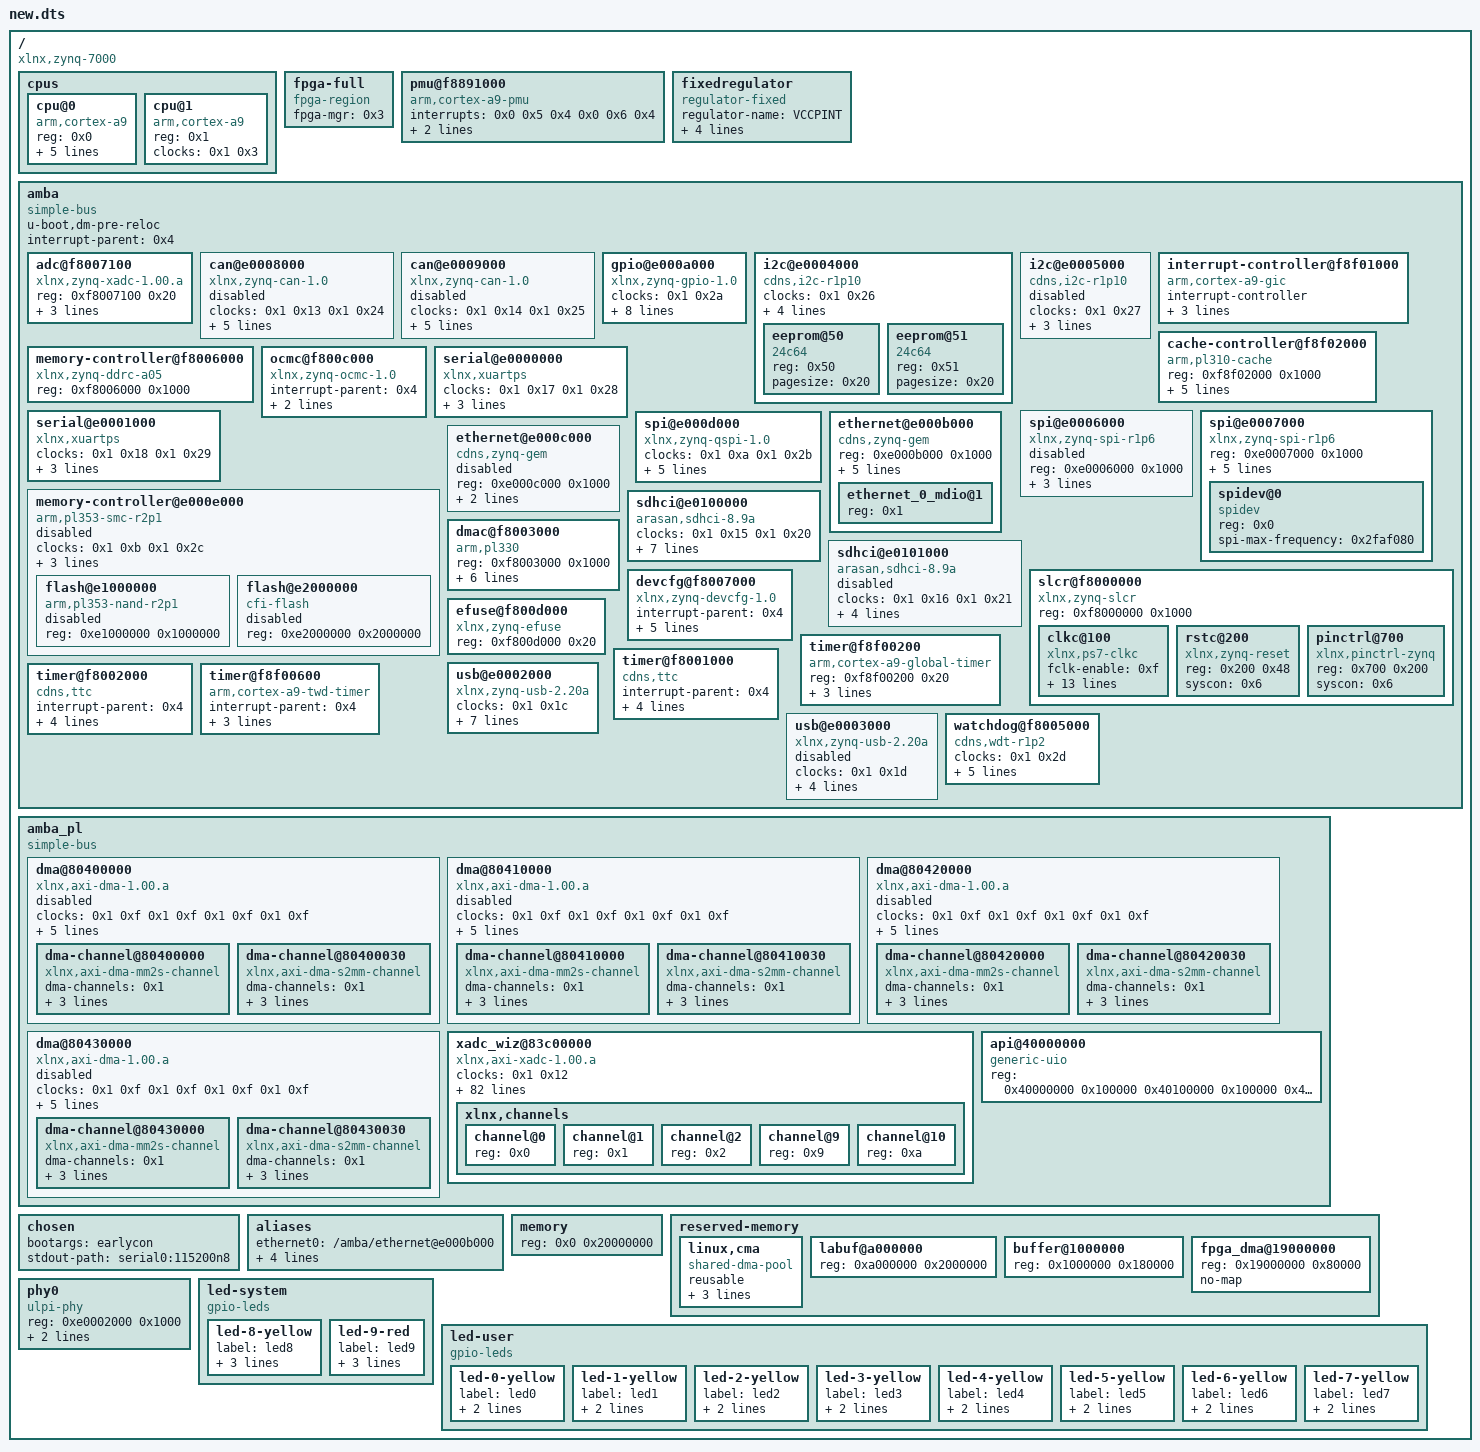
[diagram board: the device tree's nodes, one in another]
/dts-v1/;

/ {
	#address-cells = <0x1>;
	#size-cells = <0x1>;
	compatible = "xlnx,zynq-7000";

	cpus {
		#address-cells = <0x1>;
		#size-cells = <0x0>;

		cpu@0 {
			compatible = "arm,cortex-a9";
			device_type = "cpu";
			reg = <0x0>;
			clocks = <0x1 0x3>;
			clock-latency = <0x3e8>;
			cpu0-supply = <0x2>;
			operating-points = <0xa2c2a 0xf4240 0x51615 0xf4240>;
			linux,phandle = <0x9>;
			phandle = <0x9>;
		};

		cpu@1 {
			compatible = "arm,cortex-a9";
			device_type = "cpu";
			reg = <0x1>;
			clocks = <0x1 0x3>;
			linux,phandle = <0xa>;
			phandle = <0xa>;
		};
	};

	fpga-full {
		compatible = "fpga-region";
		fpga-mgr = <0x3>;
		#address-cells = <0x1>;
		#size-cells = <0x1>;
		ranges;
		linux,phandle = <0xb>;
		phandle = <0xb>;
	};

	pmu@f8891000 {
		compatible = "arm,cortex-a9-pmu";
		interrupts = <0x0 0x5 0x4 0x0 0x6 0x4>;
		interrupt-parent = <0x4>;
		reg = <0xf8891000 0x1000 0xf8893000 0x1000>;
	};

	fixedregulator {
		compatible = "regulator-fixed";
		regulator-name = "VCCPINT";
		regulator-min-microvolt = <0xf4240>;
		regulator-max-microvolt = <0xf4240>;
		regulator-boot-on;
		regulator-always-on;
		linux,phandle = <0x2>;
		phandle = <0x2>;
	};

	amba {
		u-boot,dm-pre-reloc;
		compatible = "simple-bus";
		#address-cells = <0x1>;
		#size-cells = <0x1>;
		interrupt-parent = <0x4>;
		ranges;
		linux,phandle = <0xc>;
		phandle = <0xc>;

		adc@f8007100 {
			compatible = "xlnx,zynq-xadc-1.00.a";
			reg = <0xf8007100 0x20>;
			interrupts = <0x0 0x7 0x4>;
			interrupt-parent = <0x4>;
			clocks = <0x1 0xc>;
			linux,phandle = <0xd>;
			phandle = <0xd>;
		};

		can@e0008000 {
			compatible = "xlnx,zynq-can-1.0";
			status = "disabled";
			clocks = <0x1 0x13 0x1 0x24>;
			clock-names = "can_clk", "pclk";
			reg = <0xe0008000 0x1000>;
			interrupts = <0x0 0x1c 0x4>;
			interrupt-parent = <0x4>;
			tx-fifo-depth = <0x40>;
			rx-fifo-depth = <0x40>;
			linux,phandle = <0xe>;
			phandle = <0xe>;
		};

		can@e0009000 {
			compatible = "xlnx,zynq-can-1.0";
			status = "disabled";
			clocks = <0x1 0x14 0x1 0x25>;
			clock-names = "can_clk", "pclk";
			reg = <0xe0009000 0x1000>;
			interrupts = <0x0 0x33 0x4>;
			interrupt-parent = <0x4>;
			tx-fifo-depth = <0x40>;
			rx-fifo-depth = <0x40>;
			linux,phandle = <0xf>;
			phandle = <0xf>;
		};

		gpio@e000a000 {
			compatible = "xlnx,zynq-gpio-1.0";
			#gpio-cells = <0x2>;
			clocks = <0x1 0x2a>;
			gpio-controller;
			interrupt-controller;
			#interrupt-cells = <0x2>;
			interrupt-parent = <0x4>;
			interrupts = <0x0 0x14 0x4>;
			reg = <0xe000a000 0x1000>;
			emio-gpio-width = <0x18>;
			gpio-mask-high = <0x0>;
			gpio-mask-low = <0x5600>;
			linux,phandle = <0x7>;
			phandle = <0x7>;
		};

		i2c@e0004000 {
			compatible = "cdns,i2c-r1p10";
			status = "okay";
			clocks = <0x1 0x26>;
			interrupt-parent = <0x4>;
			interrupts = <0x0 0x19 0x4>;
			reg = <0xe0004000 0x1000>;
			#address-cells = <0x1>;
			#size-cells = <0x0>;
			clock-frequency = <0x61a80>;
			linux,phandle = <0x10>;
			phandle = <0x10>;

			eeprom@50 {
				compatible = "24c64";
				reg = <0x50>;
				pagesize = <0x20>;
			};

			eeprom@51 {
				compatible = "24c64";
				reg = <0x51>;
				pagesize = <0x20>;
			};
		};

		i2c@e0005000 {
			compatible = "cdns,i2c-r1p10";
			status = "disabled";
			clocks = <0x1 0x27>;
			interrupt-parent = <0x4>;
			interrupts = <0x0 0x30 0x4>;
			reg = <0xe0005000 0x1000>;
			#address-cells = <0x1>;
			#size-cells = <0x0>;
			linux,phandle = <0x11>;
			phandle = <0x11>;
		};

		interrupt-controller@f8f01000 {
			compatible = "arm,cortex-a9-gic";
			#interrupt-cells = <0x3>;
			interrupt-controller;
			reg = <0xf8f01000 0x1000 0xf8f00100 0x100>;
			num_cpus = <0x2>;
			num_interrupts = <0x60>;
			linux,phandle = <0x4>;
			phandle = <0x4>;
		};

		cache-controller@f8f02000 {
			compatible = "arm,pl310-cache";
			reg = <0xf8f02000 0x1000>;
			interrupts = <0x0 0x2 0x4>;
			arm,data-latency = <0x3 0x2 0x2>;
			arm,tag-latency = <0x2 0x2 0x2>;
			cache-unified;
			cache-level = <0x2>;
			linux,phandle = <0x12>;
			phandle = <0x12>;
		};

		memory-controller@f8006000 {
			compatible = "xlnx,zynq-ddrc-a05";
			reg = <0xf8006000 0x1000>;
			linux,phandle = <0x13>;
			phandle = <0x13>;
		};

		ocmc@f800c000 {
			compatible = "xlnx,zynq-ocmc-1.0";
			interrupt-parent = <0x4>;
			interrupts = <0x0 0x3 0x4>;
			reg = <0xf800c000 0x1000>;
			linux,phandle = <0x14>;
			phandle = <0x14>;
		};

		serial@e0000000 {
			compatible = "xlnx,xuartps", "cdns,uart-r1p8";
			status = "okay";
			clocks = <0x1 0x17 0x1 0x28>;
			clock-names = "uart_clk", "pclk";
			reg = <0xe0000000 0x1000>;
			interrupts = <0x0 0x1b 0x4>;
			device_type = "serial";
			port-number = <0x0>;
			linux,phandle = <0x15>;
			phandle = <0x15>;
		};

		serial@e0001000 {
			compatible = "xlnx,xuartps", "cdns,uart-r1p8";
			status = "okay";
			clocks = <0x1 0x18 0x1 0x29>;
			clock-names = "uart_clk", "pclk";
			reg = <0xe0001000 0x1000>;
			interrupts = <0x0 0x32 0x4>;
			device_type = "serial";
			port-number = <0x1>;
			linux,phandle = <0x16>;
			phandle = <0x16>;
		};

		spi@e0006000 {
			compatible = "xlnx,zynq-spi-r1p6";
			reg = <0xe0006000 0x1000>;
			status = "disabled";
			interrupt-parent = <0x4>;
			interrupts = <0x0 0x1a 0x4>;
			clocks = <0x1 0x19 0x1 0x22>;
			clock-names = "ref_clk", "pclk";
			#address-cells = <0x1>;
			#size-cells = <0x0>;
			linux,phandle = <0x17>;
			phandle = <0x17>;
		};

		spi@e0007000 {
			compatible = "xlnx,zynq-spi-r1p6";
			reg = <0xe0007000 0x1000>;
			status = "okay";
			interrupt-parent = <0x4>;
			interrupts = <0x0 0x31 0x4>;
			clocks = <0x1 0x1a 0x1 0x23>;
			clock-names = "ref_clk", "pclk";
			#address-cells = <0x1>;
			#size-cells = <0x0>;
			is-decoded-cs = <0x0>;
			num-cs = <0x1>;
			linux,phandle = <0x18>;
			phandle = <0x18>;

			spidev@0 {
				compatible = "spidev";
				reg = <0x0>;
				spi-max-frequency = <0x2faf080>;
			};
		};

		spi@e000d000 {
			clock-names = "ref_clk", "pclk";
			clocks = <0x1 0xa 0x1 0x2b>;
			compatible = "xlnx,zynq-qspi-1.0";
			status = "okay";
			interrupt-parent = <0x4>;
			interrupts = <0x0 0x13 0x4>;
			reg = <0xe000d000 0x1000>;
			#address-cells = <0x1>;
			#size-cells = <0x0>;
			is-dual = <0x0>;
			num-cs = <0x1>;
			linux,phandle = <0x19>;
			phandle = <0x19>;
		};

		memory-controller@e000e000 {
			#address-cells = <0x1>;
			#size-cells = <0x1>;
			status = "disabled";
			clock-names = "memclk", "aclk";
			clocks = <0x1 0xb 0x1 0x2c>;
			compatible = "arm,pl353-smc-r2p1";
			interrupt-parent = <0x4>;
			interrupts = <0x0 0x12 0x4>;
			ranges;
			reg = <0xe000e000 0x1000>;
			linux,phandle = <0x1a>;
			phandle = <0x1a>;

			flash@e1000000 {
				status = "disabled";
				compatible = "arm,pl353-nand-r2p1";
				reg = <0xe1000000 0x1000000>;
				#address-cells = <0x1>;
				#size-cells = <0x1>;
				linux,phandle = <0x1b>;
				phandle = <0x1b>;
			};

			flash@e2000000 {
				status = "disabled";
				compatible = "cfi-flash";
				reg = <0xe2000000 0x2000000>;
				#address-cells = <0x1>;
				#size-cells = <0x1>;
				linux,phandle = <0x1c>;
				phandle = <0x1c>;
			};
		};

		ethernet@e000b000 {
			compatible = "cdns,zynq-gem", "cdns,gem";
			reg = <0xe000b000 0x1000>;
			status = "okay";
			interrupts = <0x0 0x16 0x4>;
			clocks = <0x1 0x1e 0x1 0x1e 0x1 0xd>;
			clock-names = "pclk", "hclk", "tx_clk";
			#address-cells = <0x1>;
			#size-cells = <0x0>;
			phy-mode = "rgmii-id";
			xlnx,ptp-enet-clock = <0x69f6bcb>;
			phy-handle = <0x5>;
			linux,phandle = <0x1d>;
			phandle = <0x1d>;

			ethernet_0_mdio@1 {
				reg = <0x1>;
				linux,phandle = <0x5>;
				phandle = <0x5>;
			};
		};

		ethernet@e000c000 {
			compatible = "cdns,zynq-gem", "cdns,gem";
			reg = <0xe000c000 0x1000>;
			status = "disabled";
			interrupts = <0x0 0x2d 0x4>;
			clocks = <0x1 0x1f 0x1 0x1f 0x1 0xe>;
			clock-names = "pclk", "hclk", "tx_clk";
			#address-cells = <0x1>;
			#size-cells = <0x0>;
			linux,phandle = <0x1e>;
			phandle = <0x1e>;
		};

		sdhci@e0100000 {
			compatible = "arasan,sdhci-8.9a";
			status = "okay";
			clock-names = "clk_xin", "clk_ahb";
			clocks = <0x1 0x15 0x1 0x20>;
			interrupt-parent = <0x4>;
			interrupts = <0x0 0x18 0x4>;
			reg = <0xe0100000 0x1000>;
			broken-adma2;
			xlnx,has-cd = <0x1>;
			xlnx,has-power = <0x0>;
			xlnx,has-wp = <0x1>;
			linux,phandle = <0x1f>;
			phandle = <0x1f>;
		};

		sdhci@e0101000 {
			compatible = "arasan,sdhci-8.9a";
			status = "disabled";
			clock-names = "clk_xin", "clk_ahb";
			clocks = <0x1 0x16 0x1 0x21>;
			interrupt-parent = <0x4>;
			interrupts = <0x0 0x2f 0x4>;
			reg = <0xe0101000 0x1000>;
			broken-adma2;
			linux,phandle = <0x20>;
			phandle = <0x20>;
		};

		slcr@f8000000 {
			#address-cells = <0x1>;
			#size-cells = <0x1>;
			compatible = "xlnx,zynq-slcr", "syscon", "simple-mfd";
			reg = <0xf8000000 0x1000>;
			ranges;
			linux,phandle = <0x6>;
			phandle = <0x6>;

			clkc@100 {
				#clock-cells = <0x1>;
				compatible = "xlnx,ps7-clkc";
				fclk-enable = <0xf>;
				clock-output-names = "armpll", "ddrpll", "iopll", "cpu_6or4x", "cpu_3or2x", "cpu_2x", "cpu_1x", "ddr2x", "ddr3x", "dci", "lqspi", "smc", "pcap", "gem0", "gem1", "fclk0", "fclk1", "fclk2", "fclk3", "can0", "can1", "sdio0", "sdio1", "uart0", "uart1", "spi0", "spi1", "dma", "usb0_aper", "usb1_aper", "gem0_aper", "gem1_aper", "sdio0_aper", "sdio1_aper", "spi0_aper", "spi1_aper", "can0_aper", "can1_aper", "i2c0_aper", "i2c1_aper", "uart0_aper", "uart1_aper", "gpio_aper", "lqspi_aper", "smc_aper", "swdt", "dbg_trc", "dbg_apb";
				reg = <0x100 0x100>;
				ps-clk-frequency = <0x1fca055>;
				linux,phandle = <0x1>;
				phandle = <0x1>;
			};

			rstc@200 {
				compatible = "xlnx,zynq-reset";
				reg = <0x200 0x48>;
				#reset-cells = <0x1>;
				syscon = <0x6>;
				linux,phandle = <0x21>;
				phandle = <0x21>;
			};

			pinctrl@700 {
				compatible = "xlnx,pinctrl-zynq";
				reg = <0x700 0x200>;
				syscon = <0x6>;
				linux,phandle = <0x22>;
				phandle = <0x22>;
			};
		};

		dmac@f8003000 {
			compatible = "arm,pl330", "arm,primecell";
			reg = <0xf8003000 0x1000>;
			interrupt-parent = <0x4>;
			interrupt-names = "abort", "dma0", "dma1", "dma2", "dma3", "dma4", "dma5", "dma6", "dma7";
			interrupts = <0x0 0xd 0x4 0x0 0xe 0x4 0x0 0xf 0x4 0x0 0x10 0x4 0x0 0x11 0x4 0x0 0x28 0x4 0x0 0x29 0x4 0x0 0x2a 0x4 0x0 0x2b 0x4>;
			#dma-cells = <0x1>;
			#dma-channels = <0x8>;
			#dma-requests = <0x4>;
			clocks = <0x1 0x1b>;
			clock-names = "apb_pclk";
			linux,phandle = <0x23>;
			phandle = <0x23>;
		};

		devcfg@f8007000 {
			compatible = "xlnx,zynq-devcfg-1.0";
			interrupt-parent = <0x4>;
			interrupts = <0x0 0x8 0x4>;
			reg = <0xf8007000 0x100>;
			clocks = <0x1 0xc 0x1 0xf 0x1 0x10 0x1 0x11 0x1 0x12>;
			clock-names = "ref_clk", "fclk0", "fclk1", "fclk2", "fclk3";
			syscon = <0x6>;
			linux,phandle = <0x3>;
			phandle = <0x3>;
		};

		efuse@f800d000 {
			compatible = "xlnx,zynq-efuse";
			reg = <0xf800d000 0x20>;
			linux,phandle = <0x24>;
			phandle = <0x24>;
		};

		timer@f8f00200 {
			compatible = "arm,cortex-a9-global-timer";
			reg = <0xf8f00200 0x20>;
			interrupts = <0x1 0xb 0x301>;
			interrupt-parent = <0x4>;
			clocks = <0x1 0x4>;
			linux,phandle = <0x25>;
			phandle = <0x25>;
		};

		timer@f8001000 {
			interrupt-parent = <0x4>;
			interrupts = <0x0 0xa 0x4 0x0 0xb 0x4 0x0 0xc 0x4>;
			compatible = "cdns,ttc";
			clocks = <0x1 0x6>;
			reg = <0xf8001000 0x1000>;
			linux,phandle = <0x26>;
			phandle = <0x26>;
		};

		timer@f8002000 {
			interrupt-parent = <0x4>;
			interrupts = <0x0 0x25 0x4 0x0 0x26 0x4 0x0 0x27 0x4>;
			compatible = "cdns,ttc";
			clocks = <0x1 0x6>;
			reg = <0xf8002000 0x1000>;
			linux,phandle = <0x27>;
			phandle = <0x27>;
		};

		timer@f8f00600 {
			interrupt-parent = <0x4>;
			interrupts = <0x1 0xd 0x301>;
			compatible = "arm,cortex-a9-twd-timer";
			reg = <0xf8f00600 0x20>;
			clocks = <0x1 0x4>;
			linux,phandle = <0x28>;
			phandle = <0x28>;
		};

		usb@e0002000 {
			compatible = "xlnx,zynq-usb-2.20a", "chipidea,usb2";
			status = "okay";
			clocks = <0x1 0x1c>;
			interrupt-parent = <0x4>;
			interrupts = <0x0 0x15 0x4>;
			reg = <0xe0002000 0x1000>;
			phy_type = "ulpi";
			dr_mode = "host";
			usb-reset = <0x7 0x30 0x0>;
			usb-phy = <0x8>;
			linux,phandle = <0x29>;
			phandle = <0x29>;
		};

		usb@e0003000 {
			compatible = "xlnx,zynq-usb-2.20a", "chipidea,usb2";
			status = "disabled";
			clocks = <0x1 0x1d>;
			interrupt-parent = <0x4>;
			interrupts = <0x0 0x2c 0x4>;
			reg = <0xe0003000 0x1000>;
			phy_type = "ulpi";
			linux,phandle = <0x2a>;
			phandle = <0x2a>;
		};

		watchdog@f8005000 {
			clocks = <0x1 0x2d>;
			compatible = "cdns,wdt-r1p2";
			interrupt-parent = <0x4>;
			interrupts = <0x0 0x9 0x1>;
			reg = <0xf8005000 0x1000>;
			timeout-sec = <0xa>;
			status = "okay";
			reset-on-timeout;
			linux,phandle = <0x2b>;
			phandle = <0x2b>;
		};
	};

	amba_pl {
		#address-cells = <0x1>;
		#size-cells = <0x1>;
		compatible = "simple-bus";
		ranges;
		linux,phandle = <0x2c>;
		phandle = <0x2c>;

		dma@80400000 {
			#dma-cells = <0x1>;
			clock-names = "s_axi_lite_aclk", "m_axi_sg_aclk", "m_axi_mm2s_aclk", "m_axi_s2mm_aclk";
			clocks = <0x1 0xf 0x1 0xf 0x1 0xf 0x1 0xf>;
			compatible = "xlnx,axi-dma-1.00.a";
			interrupt-parent = <0x4>;
			interrupts = <0x0 0x1e 0x4 0x0 0x34 0x4>;
			reg = <0x80400000 0x10000>;
			xlnx,addrwidth = <0x20>;
			xlnx,include-sg;
			status = "disabled";
			linux,phandle = <0x2d>;
			phandle = <0x2d>;

			dma-channel@80400000 {
				compatible = "xlnx,axi-dma-mm2s-channel";
				dma-channels = <0x1>;
				interrupts = <0x0 0x1e 0x4>;
				xlnx,datawidth = <0x20>;
				xlnx,device-id = <0x0>;
			};

			dma-channel@80400030 {
				compatible = "xlnx,axi-dma-s2mm-channel";
				dma-channels = <0x1>;
				interrupts = <0x0 0x34 0x4>;
				xlnx,datawidth = <0x20>;
				xlnx,device-id = <0x0>;
			};
		};

		dma@80410000 {
			#dma-cells = <0x1>;
			clock-names = "s_axi_lite_aclk", "m_axi_sg_aclk", "m_axi_mm2s_aclk", "m_axi_s2mm_aclk";
			clocks = <0x1 0xf 0x1 0xf 0x1 0xf 0x1 0xf>;
			compatible = "xlnx,axi-dma-1.00.a";
			interrupt-parent = <0x4>;
			interrupts = <0x0 0x20 0x4 0x0 0x1f 0x4>;
			reg = <0x80410000 0x10000>;
			xlnx,addrwidth = <0x20>;
			xlnx,include-sg;
			status = "disabled";
			linux,phandle = <0x2e>;
			phandle = <0x2e>;

			dma-channel@80410000 {
				compatible = "xlnx,axi-dma-mm2s-channel";
				dma-channels = <0x1>;
				interrupts = <0x0 0x20 0x4>;
				xlnx,datawidth = <0x20>;
				xlnx,device-id = <0x1>;
			};

			dma-channel@80410030 {
				compatible = "xlnx,axi-dma-s2mm-channel";
				dma-channels = <0x1>;
				interrupts = <0x0 0x1f 0x4>;
				xlnx,datawidth = <0x20>;
				xlnx,device-id = <0x1>;
			};
		};

		dma@80420000 {
			#dma-cells = <0x1>;
			clock-names = "s_axi_lite_aclk", "m_axi_sg_aclk", "m_axi_mm2s_aclk", "m_axi_s2mm_aclk";
			clocks = <0x1 0xf 0x1 0xf 0x1 0xf 0x1 0xf>;
			compatible = "xlnx,axi-dma-1.00.a";
			interrupt-parent = <0x4>;
			interrupts = <0x0 0x22 0x4 0x0 0x21 0x4>;
			reg = <0x80420000 0x10000>;
			xlnx,addrwidth = <0x20>;
			xlnx,include-sg;
			status = "disabled";
			linux,phandle = <0x2f>;
			phandle = <0x2f>;

			dma-channel@80420000 {
				compatible = "xlnx,axi-dma-mm2s-channel";
				dma-channels = <0x1>;
				interrupts = <0x0 0x22 0x4>;
				xlnx,datawidth = <0x10>;
				xlnx,device-id = <0x2>;
			};

			dma-channel@80420030 {
				compatible = "xlnx,axi-dma-s2mm-channel";
				dma-channels = <0x1>;
				interrupts = <0x0 0x21 0x4>;
				xlnx,datawidth = <0x10>;
				xlnx,device-id = <0x2>;
			};
		};

		dma@80430000 {
			#dma-cells = <0x1>;
			clock-names = "s_axi_lite_aclk", "m_axi_sg_aclk", "m_axi_mm2s_aclk", "m_axi_s2mm_aclk";
			clocks = <0x1 0xf 0x1 0xf 0x1 0xf 0x1 0xf>;
			compatible = "xlnx,axi-dma-1.00.a";
			interrupt-parent = <0x4>;
			interrupts = <0x0 0x24 0x4 0x0 0x23 0x4>;
			reg = <0x80430000 0x10000>;
			xlnx,addrwidth = <0x20>;
			xlnx,include-sg;
			status = "disabled";
			linux,phandle = <0x30>;
			phandle = <0x30>;

			dma-channel@80430000 {
				compatible = "xlnx,axi-dma-mm2s-channel";
				dma-channels = <0x1>;
				interrupts = <0x0 0x24 0x4>;
				xlnx,datawidth = <0x10>;
				xlnx,device-id = <0x3>;
			};

			dma-channel@80430030 {
				compatible = "xlnx,axi-dma-s2mm-channel";
				dma-channels = <0x1>;
				interrupts = <0x0 0x23 0x4>;
				xlnx,datawidth = <0x10>;
				xlnx,device-id = <0x3>;
			};
		};

		xadc_wiz@83c00000 {
			clock-names = "ref_clk";
			clocks = <0x1 0x12>;
			compatible = "xlnx,axi-xadc-1.00.a";
			interrupt-parent = <0x4>;
			interrupts = <0x0 0x1d 0x4>;
			reg = <0x83c00000 0x10000>;
			xlnx,alarm-limit-r0 = <0xb5ed>;
			xlnx,alarm-limit-r1 = <0x57e4>;
			xlnx,alarm-limit-r10 = <0x5555>;
			xlnx,alarm-limit-r11 = <0x5111>;
			xlnx,alarm-limit-r12 = <0x9999>;
			xlnx,alarm-limit-r13 = <0x91eb>;
			xlnx,alarm-limit-r14 = <0x6aaa>;
			xlnx,alarm-limit-r15 = <0x6666>;
			xlnx,alarm-limit-r2 = <0xa147>;
			xlnx,alarm-limit-r3 = <0xca33>;
			xlnx,alarm-limit-r4 = <0xa93a>;
			xlnx,alarm-limit-r5 = <0x52c6>;
			xlnx,alarm-limit-r6 = <0x9555>;
			xlnx,alarm-limit-r7 = <0xae4e>;
			xlnx,alarm-limit-r8 = <0x5999>;
			xlnx,alarm-limit-r9 = <0x5111>;
			xlnx,configuration-r0 = <0x0>;
			xlnx,configuration-r1 = <0x8100>;
			xlnx,configuration-r2 = <0x400>;
			xlnx,dclk-frequency = <0x64>;
			xlnx,external-mux = "none";
			xlnx,external-mux-channel = "VP_VN";
			xlnx,external-muxaddr-enable = <0x0>;
			xlnx,fifo-depth = <0x7>;
			xlnx,has-axi = <0x1>;
			xlnx,has-axi4stream = <0x0>;
			xlnx,has-busy = <0x1>;
			xlnx,has-channel = <0x1>;
			xlnx,has-convst = <0x0>;
			xlnx,has-convstclk = <0x0>;
			xlnx,has-dclk = <0x1>;
			xlnx,has-drp = <0x0>;
			xlnx,has-eoc = <0x1>;
			xlnx,has-eos = <0x1>;
			xlnx,has-external-mux = <0x0>;
			xlnx,has-jtagbusy = <0x0>;
			xlnx,has-jtaglocked = <0x0>;
			xlnx,has-jtagmodified = <0x0>;
			xlnx,has-ot-alarm = <0x1>;
			xlnx,has-reset = <0x0>;
			xlnx,has-temp-bus = <0x0>;
			xlnx,has-user-temp-alarm = <0x1>;
			xlnx,has-vbram-alarm = <0x0>;
			xlnx,has-vccaux-alarm = <0x1>;
			xlnx,has-vccddro-alarm = <0x1>;
			xlnx,has-vccint-alarm = <0x1>;
			xlnx,has-vccpaux-alarm = <0x1>;
			xlnx,has-vccpint-alarm = <0x1>;
			xlnx,has-vn = <0x1>;
			xlnx,has-vp = <0x1>;
			xlnx,include-intr = <0x1>;
			xlnx,sampling-rate = "961538.4615384615";
			xlnx,sequence-r0 = <0x800>;
			xlnx,sequence-r1 = <0x303>;
			xlnx,sequence-r2 = <0x0>;
			xlnx,sequence-r3 = <0x0>;
			xlnx,sequence-r4 = <0x0>;
			xlnx,sequence-r5 = <0x0>;
			xlnx,sequence-r6 = <0x0>;
			xlnx,sequence-r7 = <0x0>;
			xlnx,sim-file-name = "design";
			xlnx,sim-file-rel-path = "./";
			xlnx,sim-file-sel = "Default";
			xlnx,vaux0 = <0x1>;
			xlnx,vaux1 = <0x1>;
			xlnx,vaux10 = <0x0>;
			xlnx,vaux11 = <0x0>;
			xlnx,vaux12 = <0x0>;
			xlnx,vaux13 = <0x0>;
			xlnx,vaux14 = <0x0>;
			xlnx,vaux15 = <0x0>;
			xlnx,vaux2 = <0x0>;
			xlnx,vaux3 = <0x0>;
			xlnx,vaux4 = <0x0>;
			xlnx,vaux5 = <0x0>;
			xlnx,vaux6 = <0x0>;
			xlnx,vaux7 = <0x0>;
			xlnx,vaux8 = <0x1>;
			xlnx,vaux9 = <0x1>;
			linux,phandle = <0x31>;
			phandle = <0x31>;

			xlnx,channels {
				#address-cells = <0x1>;
				#size-cells = <0x0>;

				channel@0 {
					reg = <0x0>;
				};

				channel@1 {
					reg = <0x1>;
				};

				channel@2 {
					reg = <0x2>;
				};

				channel@9 {
					reg = <0x9>;
				};

				channel@10 {
					reg = <0xa>;
				};
			};
		};

		api@40000000 {
			compatible = "generic-uio";
			reg = <0x40000000 0x100000 0x40100000 0x100000 0x40200000 0x100000 0x40300000 0x100000 0x40400000 0x100000 0x40500000 0x100000 0x40600000 0x100000 0x40700000 0x100000>;
			reg-names = "hk", "acq", "asg", "pid", "ams", "daisy", "unused", "test";
			linux,phandle = <0x32>;
			phandle = <0x32>;
		};
	};

	chosen {
		bootargs = "earlycon";
		stdout-path = "serial0:115200n8";
	};

	aliases {
		ethernet0 = "/amba/ethernet@e000b000";
		serial0 = "/amba/serial@e0000000";
		serial1 = "/amba/serial@e0001000";
		spi0 = "/amba/spi@e000d000";
		spi1 = "/amba/spi@e0007000";
	};

	memory {
		device_type = "memory";
		reg = <0x0 0x20000000>;
	};

	reserved-memory {
		#address-cells = <0x1>;
		#size-cells = <0x1>;
		ranges;

		linux,cma {
			compatible = "shared-dma-pool";
			reusable;
			size = <0x1000000>;
			alignment = <0x2000>;
			linux,cma-default;
		};

		labuf@a000000 {
			reg = <0xa000000 0x2000000>;
			linux,phandle = <0x33>;
			phandle = <0x33>;
		};

		buffer@1000000 {
			reg = <0x1000000 0x180000>;
			linux,phandle = <0x34>;
			phandle = <0x34>;
		};

		fpga_dma@19000000 {
			reg = <0x19000000 0x80000>;
			no-map;
		};
	};

	phy0 {
		compatible = "ulpi-phy";
		#phy-cells = <0x0>;
		reg = <0xe0002000 0x1000>;
		view-port = <0x170>;
		drv-vbus;
		linux,phandle = <0x8>;
		phandle = <0x8>;
	};

	led-system {
		compatible = "gpio-leds";

		led-8-yellow {
			label = "led8";
			gpios = <0x7 0x0 0x0>;
			default-state = "off";
			linux,default-trigger = "mmc0";
		};

		led-9-red {
			label = "led9";
			gpios = <0x7 0x7 0x0>;
			default-state = "off";
			linux,default-trigger = "heartbeat";
		};
	};

	led-user {
		compatible = "gpio-leds";

		led-0-yellow {
			label = "led0";
			gpios = <0x7 0x36 0x0>;
			default-state = "off";
		};

		led-1-yellow {
			label = "led1";
			gpios = <0x7 0x37 0x0>;
			default-state = "off";
		};

		led-2-yellow {
			label = "led2";
			gpios = <0x7 0x38 0x0>;
			default-state = "off";
		};

		led-3-yellow {
			label = "led3";
			gpios = <0x7 0x39 0x0>;
			default-state = "off";
		};

		led-4-yellow {
			label = "led4";
			gpios = <0x7 0x3a 0x0>;
			default-state = "off";
		};

		led-5-yellow {
			label = "led5";
			gpios = <0x7 0x3b 0x0>;
			default-state = "off";
		};

		led-6-yellow {
			label = "led6";
			gpios = <0x7 0x3c 0x0>;
			default-state = "off";
		};

		led-7-yellow {
			label = "led7";
			gpios = <0x7 0x3d 0x0>;
			default-state = "off";
		};
	};

	__symbols__ {
		cpu0 = "/cpus/cpu@0";
		cpu1 = "/cpus/cpu@1";
		fpga_full = "/fpga-full";
		regulator_vccpint = "/fixedregulator";
		amba = "/amba";
		adc = "/amba/adc@f8007100";
		can0 = "/amba/can@e0008000";
		can1 = "/amba/can@e0009000";
		gpio0 = "/amba/gpio@e000a000";
		i2c0 = "/amba/i2c@e0004000";
		i2c1 = "/amba/i2c@e0005000";
		intc = "/amba/interrupt-controller@f8f01000";
		L2 = "/amba/cache-controller@f8f02000";
		mc = "/amba/memory-controller@f8006000";
		ocmc = "/amba/ocmc@f800c000";
		uart0 = "/amba/serial@e0000000";
		uart1 = "/amba/serial@e0001000";
		spi0 = "/amba/spi@e0006000";
		spi1 = "/amba/spi@e0007000";
		qspi = "/amba/spi@e000d000";
		smcc = "/amba/memory-controller@e000e000";
		nand0 = "/amba/memory-controller@e000e000/flash@e1000000";
		nor0 = "/amba/memory-controller@e000e000/flash@e2000000";
		gem0 = "/amba/ethernet@e000b000";
		ethernet_0_mdio = "/amba/ethernet@e000b000/ethernet_0_mdio@1";
		gem1 = "/amba/ethernet@e000c000";
		sdhci0 = "/amba/sdhci@e0100000";
		sdhci1 = "/amba/sdhci@e0101000";
		slcr = "/amba/slcr@f8000000";
		clkc = "/amba/slcr@f8000000/clkc@100";
		rstc = "/amba/slcr@f8000000/rstc@200";
		pinctrl0 = "/amba/slcr@f8000000/pinctrl@700";
		dmac_s = "/amba/dmac@f8003000";
		devcfg = "/amba/devcfg@f8007000";
		efuse = "/amba/efuse@f800d000";
		global_timer = "/amba/timer@f8f00200";
		ttc0 = "/amba/timer@f8001000";
		ttc1 = "/amba/timer@f8002000";
		scutimer = "/amba/timer@f8f00600";
		usb0 = "/amba/usb@e0002000";
		usb1 = "/amba/usb@e0003000";
		watchdog0 = "/amba/watchdog@f8005000";
		amba_pl = "/amba_pl";
		axi_dma_0 = "/amba_pl/dma@80400000";
		axi_dma_1 = "/amba_pl/dma@80410000";
		axi_dma_2 = "/amba_pl/dma@80420000";
		axi_dma_3 = "/amba_pl/dma@80430000";
		xadc = "/amba_pl/xadc_wiz@83c00000";
		api = "/amba_pl/api@40000000";
		rprx_reserverd = "/reserved-memory/labuf@a000000";
		streaming_reserved = "/reserved-memory/buffer@1000000";
		usb_phy0 = "/phy0";
	};
};
